# ARMv7-M-MPU register map
Registers from a debugger description file.
Registers are 32-bit, access not given, no defined reset value unless marked. A register's access mark holds for its fields unless they carry their own. Addresses are absolute; registers are grouped by the start of their names; lines under a group give offsets from that group; [hi:lo] are bit positions; {n}, {i} and the like mark numbered series; 'fields as' and 'values as' point back to an identical list; <NAME> marks a mode.

## MPU
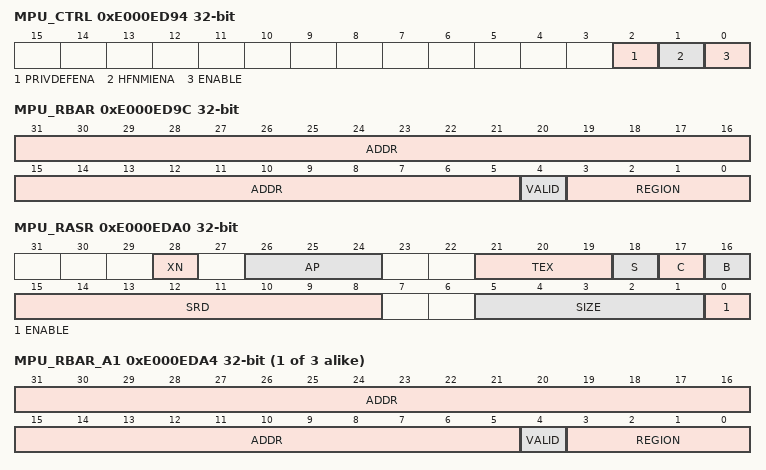
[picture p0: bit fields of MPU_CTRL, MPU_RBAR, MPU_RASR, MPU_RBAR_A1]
0xE000ED94 MPU_CTRL
  [2] PRIVDEFENA, [1] HFNMIENA, [0] ENABLE
0xE000ED98 MPU_RNR
  [7:0] REGION
0xE000ED9C MPU_RBAR
  [31:5] ADDR, [4] VALID, [3:0] REGION
0xE000EDA0 MPU_RASR
  [28] XN, [26:24] AP, [21:19] TEX, [18] S, [17] C, [16] B, [15:8] SRD, [5:1] SIZE, [0] ENABLE
{0xE000ED9C+8i} MPU_RBAR_A{i} (i=1..3)
  [31:5] ADDR, [4] VALID, [3:0] REGION
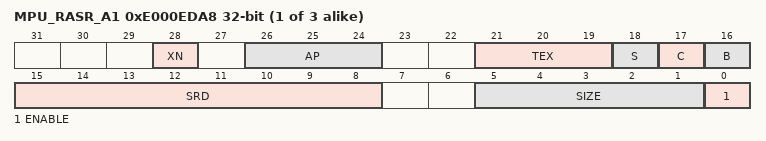
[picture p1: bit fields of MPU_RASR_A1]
{0xE000EDA0+8i} MPU_RASR_A{i} (i=1..3)
  fields as MPU_RASR
